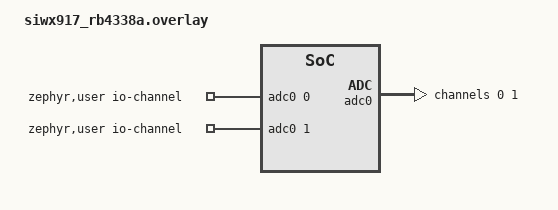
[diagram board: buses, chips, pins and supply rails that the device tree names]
/*
 * Copyright (c) 2025 Silicon Laboratories Inc.
 *
 * SPDX-License-Identifier: Apache-2.0
 */

/ {
	zephyr,user {
		io-channels = <&adc0 0>, <&adc0 1>;
	};
};

&pinctrl0 {
	adc0_default: adc0_default {
		group {
			pinmux = <AGPIO_ULP1>, <ADC_TOPGPIO_HP27>;
		};
	};
};

&adc0 {
	pinctrl-0 = <&adc0_default>;
	pinctrl-names = "default";
	silabs,adc-ref-voltage = <3300>;

	channel@0 {
		reg = <0>;
		zephyr,gain = "ADC_GAIN_1";
		zephyr,reference = "ADC_REF_INTERNAL";
		zephyr,acquisition-time = <0>;
		zephyr,resolution = <12>;
		zephyr,input-positive = <10>;
	};

	channel@1 {
		reg = <1>;
		zephyr,gain = "ADC_GAIN_1";
		zephyr,reference = "ADC_REF_INTERNAL";
		zephyr,acquisition-time = <0>;
		zephyr,resolution = <12>;
		zephyr,input-positive = <7>;
	};
	status = "okay";
};
